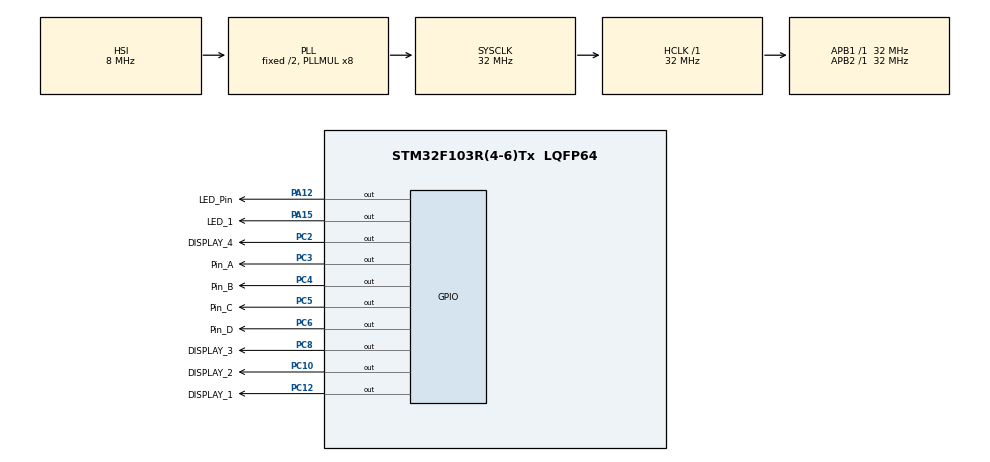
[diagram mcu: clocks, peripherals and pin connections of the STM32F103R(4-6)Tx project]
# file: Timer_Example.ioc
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Mcu.Family=STM32F1
PC15-OSC32_OUT.Mode=LSE-External-Oscillator
PD1-OSC_OUT.Mode=HSE-External-Oscillator
PC10.GPIO_Label=DISPLAY_2
PC10.Signal=GPIO_Output
PC12.Signal=GPIO_Output
PC8.Signal=GPIO_Output
PC4.Signal=GPIO_Output
PC2.Signal=GPIO_Output
PC6.Signal=GPIO_Output
PC6.GPIO_Label=Pin_D
VP_RTC_VS_RTC_Activate.Mode=RTC_Enabled
RTC.WeekDay=RTC_WEEKDAY_TUESDAY
NVIC.TIM1_UP_IRQn=true\:0\:0\:false\:false\:true\:true\:true
PD0-OSC_IN.Signal=RCC_OSC_IN
PC14-OSC32_IN.Signal=RCC_OSC32_IN
PA12.GPIO_Label=LED_Pin
RCC.SYSCLKSource=RCC_SYSCLKSOURCE_PLLCLK
ProjectManager.StackSize=0x400
PD1-OSC_OUT.Signal=RCC_OSC_OUT
PC8.GPIO_Label=DISPLAY_3
PA13.Signal=SYS_JTMS-SWDIO
PA15.GPIO_Label=LED_1
PA12.Signal=GPIO_Output
TIM1.Prescaler=3199
ProjectManager.TargetToolchain=STM32CubeIDE
RTC.Year=21
RCC.HCLKFreq_Value=32000000
RCC.APB2TimFreq_Value=32000000
PC3.Signal=GPIO_Output
RTC.Format=RTC_FORMAT_BIN
RCC.USBFreq_Value=32000000
PC15-OSC32_OUT.Signal=RCC_OSC32_OUT
RCC.AHBFreq_Value=32000000
PD0-OSC_IN.Mode=HSE-External-Oscillator
RTC.Minutes=44
board=custom
RCC.RTCClockSelection=RCC_RTCCLKSOURCE_LSE
RCC.PLLMUL=RCC_PLL_MUL8
RCC.APB2Freq_Value=32000000
RTC.Month=RTC_MONTH_JUNE
PC14-OSC32_IN.Mode=LSE-External-Oscillator
PC4.GPIO_Label=Pin_B
PA14.Mode=Serial_Wire
PA13.Mode=Serial_Wire
Mcu.Name=STM32F103R(4-6)Tx
VP_TIM1_VS_ClockSourceINT.Mode=Internal
RCC.SYSCLKFreq_VALUE=32000000
RTC.Hours=13
Mcu.Package=LQFP64
PC5.GPIO_Label=Pin_C
PC12.GPIO_Label=DISPLAY_1
PA14.Signal=SYS_JTCK-SWCLK
VP_RTC_VS_RTC_Calendar.Mode=RTC_Calendar
PA15.Signal=GPIO_Output
ProjectManager.HeapSize=0x200
NVIC.PriorityGroup=NVIC_PRIORITYGROUP_4
RCC.APB1TimFreq_Value=32000000
PC3.GPIO_Label=Pin_A
PC5.Signal=GPIO_Output
TIM1.Period=50
RTC.Seconds=50
RCC.APB1Freq_Value=32000000
PC2.GPIO_Label=DISPLAY_4

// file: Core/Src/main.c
/* USER CODE BEGIN Header */
/**
  ******************************************************************************
  * @file           : main.c
  * @brief          : Main program body
  ******************************************************************************
  * @attention
  *
  * <h2><center>&copy; Copyright (c) 2021 STMicroelectronics.
  * All rights reserved.</center></h2>
  *
  * This software component is licensed by ST under BSD 3-Clause license,
  * the "License"; You may not use this file except in compliance with the
  * License. You may obtain a copy of the License at:
  *                        opensource.org/licenses/BSD-3-Clause
  *
  ******************************************************************************
  */
/* USER CODE END Header */
#include "main.h"

/* USER CODE BEGIN PD */
RTC_TimeTypeDef sTime;
RTC_DateTypeDef DateToUpdate ;
uint8_t saat ;
uint8_t dakika ;
/* USER CODE END PD */

RTC_HandleTypeDef hrtc;

TIM_HandleTypeDef htim1;

void SystemClock_Config(void);
static void MX_GPIO_Init(void);
static void MX_TIM1_Init(void);
static void MX_RTC_Init(void);

/* USER CODE BEGIN 0 */
//extern unsigned int new_value ;
/* USER CODE END 0 */

int main(void)
{

  /* MCU Configuration--------------------------------------------------------*/

  /* Reset of all peripherals, Initializes the Flash interface and the Systick. */
  HAL_Init();

  /* Configure the system clock */
  SystemClock_Config();

  /* Initialize all configured peripherals */
  MX_GPIO_Init();
  MX_TIM1_Init();
  MX_RTC_Init();
  /* USER CODE BEGIN 2 */
  HAL_TIM_Base_Start_IT(&htim1);
  /* USER CODE END 2 */

  /* Infinite loop */
  while (1)
  {

    /* USER CODE BEGIN 3 */
      HAL_RTC_GetTime(&hrtc, &sTime, RTC_FORMAT_BIN);
      saat = sTime.Hours;
      dakika = sTime.Minutes;
      HAL_GPIO_WritePin(LED_Pin_GPIO_Port, LED_Pin_Pin,SET);
      HAL_Delay(500);
      HAL_GPIO_WritePin(LED_Pin_GPIO_Port, LED_Pin_Pin,RESET);
      HAL_Delay(500);

  }
  /* USER CODE END 3 */
}

void SystemClock_Config(void)
{
  RCC_OscInitTypeDef RCC_OscInitStruct = {0};
  RCC_ClkInitTypeDef RCC_ClkInitStruct = {0};
  RCC_PeriphCLKInitTypeDef PeriphClkInit = {0};

  /** Initializes the RCC Oscillators according to the specified parameters
  * in the RCC_OscInitTypeDef structure.
  */
  RCC_OscInitStruct.OscillatorType = RCC_OSCILLATORTYPE_HSI|RCC_OSCILLATORTYPE_LSE;
  RCC_OscInitStruct.LSEState = RCC_LSE_ON;
  RCC_OscInitStruct.HSIState = RCC_HSI_ON;
  RCC_OscInitStruct.HSICalibrationValue = RCC_HSICALIBRATION_DEFAULT;
  RCC_OscInitStruct.PLL.PLLState = RCC_PLL_ON;
  RCC_OscInitStruct.PLL.PLLSource = RCC_PLLSOURCE_HSI_DIV2;
  RCC_OscInitStruct.PLL.PLLMUL = RCC_PLL_MUL8;
  if (HAL_RCC_OscConfig(&RCC_OscInitStruct) != HAL_OK)
  {
    Error_Handler();
  }
  /** Initializes the CPU, AHB and APB buses clocks
  */
  RCC_ClkInitStruct.ClockType = RCC_CLOCKTYPE_HCLK|RCC_CLOCKTYPE_SYSCLK
                              |RCC_CLOCKTYPE_PCLK1|RCC_CLOCKTYPE_PCLK2;
  RCC_ClkInitStruct.SYSCLKSource = RCC_SYSCLKSOURCE_PLLCLK;
  RCC_ClkInitStruct.AHBCLKDivider = RCC_SYSCLK_DIV1;
  RCC_ClkInitStruct.APB1CLKDivider = RCC_HCLK_DIV1;
  RCC_ClkInitStruct.APB2CLKDivider = RCC_HCLK_DIV1;

  if (HAL_RCC_ClockConfig(&RCC_ClkInitStruct, FLASH_LATENCY_1) != HAL_OK)
  {
    Error_Handler();
  }
  PeriphClkInit.PeriphClockSelection = RCC_PERIPHCLK_RTC;
  PeriphClkInit.RTCClockSelection = RCC_RTCCLKSOURCE_LSE;
  if (HAL_RCCEx_PeriphCLKConfig(&PeriphClkInit) != HAL_OK)
  {
    Error_Handler();
  }
}

static void MX_RTC_Init(void)
{

  RTC_TimeTypeDef sTime = {0};
  RTC_DateTypeDef DateToUpdate = {0};

  /** Initialize RTC Only
  */
  hrtc.Instance = RTC;
  hrtc.Init.AsynchPrediv = RTC_AUTO_1_SECOND;
  hrtc.Init.OutPut = RTC_OUTPUTSOURCE_ALARM;
  if (HAL_RTC_Init(&hrtc) != HAL_OK)
  {
    Error_Handler();
  }

  /** Initialize RTC and set the Time and Date
  */
  sTime.Hours = 13;
  sTime.Minutes = 44;
  sTime.Seconds = 50;

  if (HAL_RTC_SetTime(&hrtc, &sTime, RTC_FORMAT_BIN) != HAL_OK)
  {
    Error_Handler();
  }
  DateToUpdate.WeekDay = RTC_WEEKDAY_TUESDAY;
  DateToUpdate.Month = RTC_MONTH_JUNE;
  DateToUpdate.Date = 1;
  DateToUpdate.Year = 21;

  if (HAL_RTC_SetDate(&hrtc, &DateToUpdate, RTC_FORMAT_BIN) != HAL_OK)
  {
    Error_Handler();
  }

}

static void MX_TIM1_Init(void)
{

  TIM_ClockConfigTypeDef sClockSourceConfig = {0};
  TIM_MasterConfigTypeDef sMasterConfig = {0};

  htim1.Instance = TIM1;
  htim1.Init.Prescaler = 3199;
  htim1.Init.CounterMode = TIM_COUNTERMODE_UP;
  htim1.Init.Period = 50;
  htim1.Init.ClockDivision = TIM_CLOCKDIVISION_DIV1;
  htim1.Init.RepetitionCounter = 0;
  htim1.Init.AutoReloadPreload = TIM_AUTORELOAD_PRELOAD_DISABLE;
  if (HAL_TIM_Base_Init(&htim1) != HAL_OK)
  {
    Error_Handler();
  }
  sClockSourceConfig.ClockSource = TIM_CLOCKSOURCE_INTERNAL;
  if (HAL_TIM_ConfigClockSource(&htim1, &sClockSourceConfig) != HAL_OK)
  {
    Error_Handler();
  }
  sMasterConfig.MasterOutputTrigger = TIM_TRGO_RESET;
  sMasterConfig.MasterSlaveMode = TIM_MASTERSLAVEMODE_DISABLE;
  if (HAL_TIMEx_MasterConfigSynchronization(&htim1, &sMasterConfig) != HAL_OK)
  {
    Error_Handler();
  }

}

static void MX_GPIO_Init(void)
{
  GPIO_InitTypeDef GPIO_InitStruct = {0};

  /* GPIO Ports Clock Enable */
  __HAL_RCC_GPIOC_CLK_ENABLE();
  __HAL_RCC_GPIOD_CLK_ENABLE();
  __HAL_RCC_GPIOA_CLK_ENABLE();

  /*Configure GPIO pin Output Level */
  HAL_GPIO_WritePin(GPIOC, DISPLAY_4_Pin|Pin_A_Pin|Pin_B_Pin|Pin_C_Pin
                          |Pin_D_Pin|DISPLAY_3_Pin|DISPLAY_2_Pin|DISPLAY_1_Pin, GPIO_PIN_RESET);

  /*Configure GPIO pin Output Level */
  HAL_GPIO_WritePin(GPIOA, LED_Pin_Pin|LED_1_Pin, GPIO_PIN_RESET);

  /*Configure GPIO pins : DISPLAY_4_Pin Pin_A_Pin Pin_B_Pin Pin_C_Pin
                           Pin_D_Pin DISPLAY_3_Pin DISPLAY_2_Pin DISPLAY_1_Pin */
  GPIO_InitStruct.Pin = DISPLAY_4_Pin|Pin_A_Pin|Pin_B_Pin|Pin_C_Pin
                          |Pin_D_Pin|DISPLAY_3_Pin|DISPLAY_2_Pin|DISPLAY_1_Pin;
  GPIO_InitStruct.Mode = GPIO_MODE_OUTPUT_PP;
  GPIO_InitStruct.Pull = GPIO_NOPULL;
  GPIO_InitStruct.Speed = GPIO_SPEED_FREQ_LOW;
  HAL_GPIO_Init(GPIOC, &GPIO_InitStruct);

  /*Configure GPIO pins : LED_Pin_Pin LED_1_Pin */
  GPIO_InitStruct.Pin = LED_Pin_Pin|LED_1_Pin;
  GPIO_InitStruct.Mode = GPIO_MODE_OUTPUT_PP;
  GPIO_InitStruct.Pull = GPIO_NOPULL;
  GPIO_InitStruct.Speed = GPIO_SPEED_FREQ_LOW;
  HAL_GPIO_Init(GPIOA, &GPIO_InitStruct);

}

void Error_Handler(void)
{
  __disable_irq();
  while (1)
  {
  }
}

/************************ (C) COPYRIGHT STMicroelectronics *****END OF FILE****/
